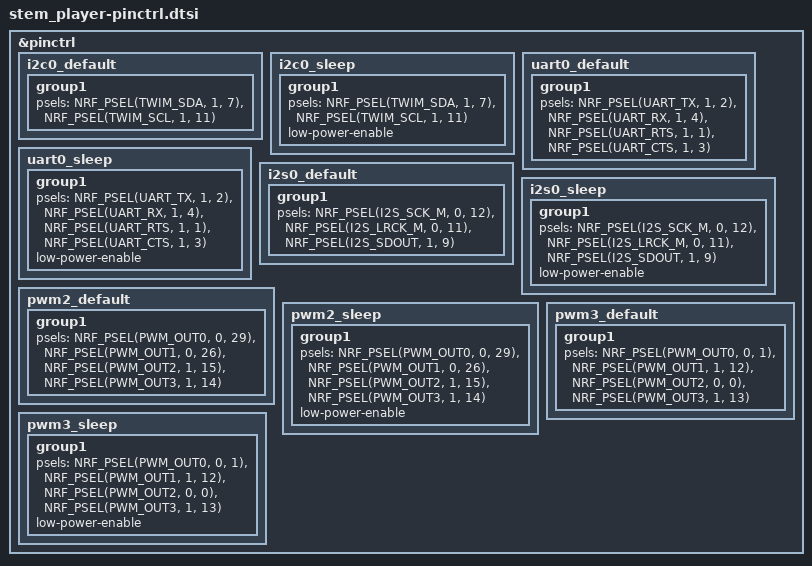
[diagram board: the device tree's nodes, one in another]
/*
 * Pin Control Definitions for Stem Player SP-1
 */

&pinctrl {
    /* I2C0: CS42L42 and TAS2505 */
    i2c0_default: i2c0_default {
        group1 {
            psels = <NRF_PSEL(TWIM_SDA, 1, 7)>,  /* P1.07 */
                    <NRF_PSEL(TWIM_SCL, 1, 11)>; /* P1.11 */
        };
    };
    i2c0_sleep: i2c0_sleep {
        group1 {
            psels = <NRF_PSEL(TWIM_SDA, 1, 7)>,
                    <NRF_PSEL(TWIM_SCL, 1, 11)>;
            low-power-enable;
        };
    };

    /* UART0: CYBT-353027-02 Bluetooth Module */
    uart0_default: uart0_default {
        group1 {
            psels = <NRF_PSEL(UART_TX, 1, 2)>,   /* P1.02 */
                    <NRF_PSEL(UART_RX, 1, 4)>,   /* P1.04 */
                    <NRF_PSEL(UART_RTS, 1, 1)>,  /* P1.01 */
                    <NRF_PSEL(UART_CTS, 1, 3)>;  /* P1.03 */
        };
    };
    uart0_sleep: uart0_sleep {
        group1 {
            psels = <NRF_PSEL(UART_TX, 1, 2)>,
                    <NRF_PSEL(UART_RX, 1, 4)>,
                    <NRF_PSEL(UART_RTS, 1, 1)>,
                    <NRF_PSEL(UART_CTS, 1, 3)>;
            low-power-enable;
        };
    };

    /* I2S0: Audio Streaming (master mode — nRF52840 drives BCLK/LRCK) */
    i2s0_default: i2s0_default {
        group1 {
            psels = <NRF_PSEL(I2S_SCK_M, 0, 12)>,    /* P0.12 BCLK output */
                    <NRF_PSEL(I2S_LRCK_M, 0, 11)>,   /* P0.11 LRCK output */
                    <NRF_PSEL(I2S_SDOUT, 1, 9)>;     /* P1.09 data output */
        };
    };
    i2s0_sleep: i2s0_sleep {
        group1 {
            psels = <NRF_PSEL(I2S_SCK_M, 0, 12)>,
                    <NRF_PSEL(I2S_LRCK_M, 0, 11)>,
                    <NRF_PSEL(I2S_SDOUT, 1, 9)>;
            low-power-enable;
        };
    };

    /* PWM2: Track LEDs */
    pwm2_default: pwm2_default {
        group1 {
            psels = <NRF_PSEL(PWM_OUT0, 0, 29)>, /* P0.29 */
                    <NRF_PSEL(PWM_OUT1, 0, 26)>, /* P0.26 */
                    <NRF_PSEL(PWM_OUT2, 1, 15)>, /* P1.15 */
                    <NRF_PSEL(PWM_OUT3, 1, 14)>; /* P1.14 */
        };
    };
    pwm2_sleep: pwm2_sleep {
        group1 {
            psels = <NRF_PSEL(PWM_OUT0, 0, 29)>,
                    <NRF_PSEL(PWM_OUT1, 0, 26)>,
                    <NRF_PSEL(PWM_OUT2, 1, 15)>,
                    <NRF_PSEL(PWM_OUT3, 1, 14)>;
            low-power-enable;
        };
    };

    /* PWM3: Playback LEDs */
    pwm3_default: pwm3_default {
        group1 {
            psels = <NRF_PSEL(PWM_OUT0, 0, 1)>,  /* P0.01 */
                    <NRF_PSEL(PWM_OUT1, 1, 12)>, /* P1.12 */
                    <NRF_PSEL(PWM_OUT2, 0, 0)>,  /* P0.00 */
                    <NRF_PSEL(PWM_OUT3, 1, 13)>; /* P1.13 */
        };
    };
    pwm3_sleep: pwm3_sleep {
        group1 {
            psels = <NRF_PSEL(PWM_OUT0, 0, 1)>,
                    <NRF_PSEL(PWM_OUT1, 1, 12)>,
                    <NRF_PSEL(PWM_OUT2, 0, 0)>,
                    <NRF_PSEL(PWM_OUT3, 1, 13)>;
            low-power-enable;
        };
    };
};
